# ML630Q466 register map
Vendor: LAPIS Semiconductor Co.,Ltd.; File version: 1.00
CPU: CM0PLUS r0p1, little endian, no MPU, no FPU, 2 interrupt priority bits
Registers are 32-bit, read-write, no defined reset value unless marked. A register's access mark holds for its fields unless they carry their own. Offsets are from the block's base; [hi:lo] are bit positions; {n}, {i} and the like mark numbered series.

## RESET
Base 0x5C000200
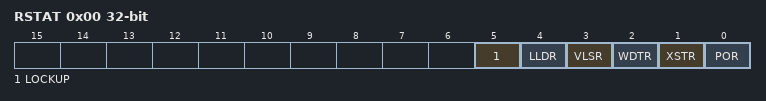
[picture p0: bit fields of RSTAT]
0x00 RSTAT — Reset status register
  [5] LOCKUP, [4] LLDR, [3] VLSR, [2] WDTR, [1] XSTR, [0] POR
0x04 LOCKUPEN — LOCKUP reset setting register
  [0] EN

## CLKCNT
Base 0x5C000300
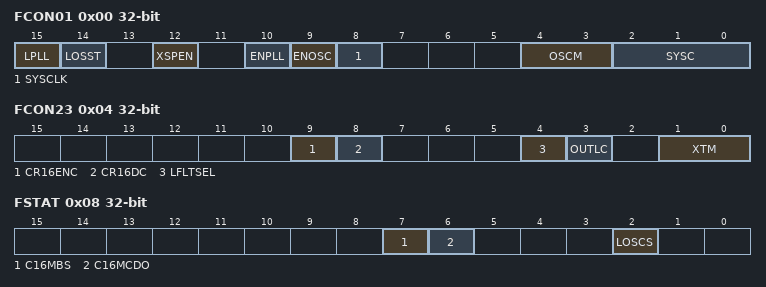
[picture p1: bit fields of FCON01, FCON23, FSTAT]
0x00 FCON01 access per field — Frequency control register 01
  [15] LPLL ro, [14] LOSST ro, [12] XSPEN rw, [10] ENPLL rw, [9] ENOSC rw, [8] SYSCLK rw, [4:3] OSCM rw, [2:0] SYSC rw
0x04 FCON23 — Frequency control register 23
  [9] CR16ENC, [8] CR16DC, [4] LFLTSEL, [3] OUTLC, [1:0] XTM
0x08 FSTAT ro — Frequency status register
  [7] C16MBS, [6] C16MCDO, [2] LOSCS

## NINT
Base 0x5C000100
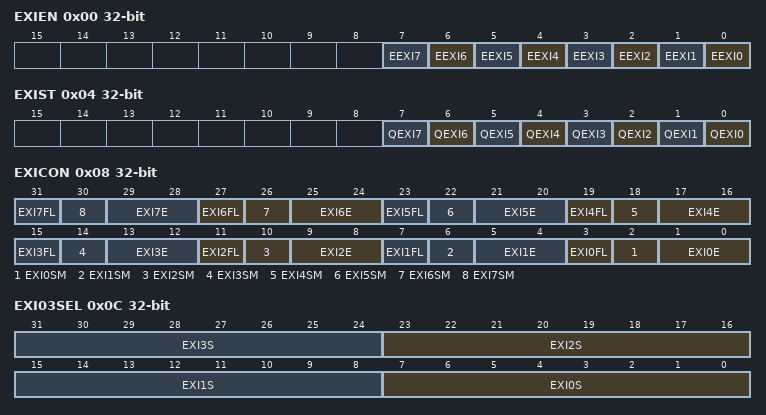
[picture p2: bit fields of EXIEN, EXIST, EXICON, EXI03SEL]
0x00 EXIEN — External interrupt enable register
  [n] EEXI{n} (n=0..7)
0x04 EXIST — External Interrupt status register
  [n] QEXI{n} (n=0..7)
0x08 EXICON — External interrupt control register
  [4n+3] EXI{n}FL (n=0..7), [4n+2] EXI{n}SM (n=0..7), [4n+1:4n] EXI{n}E (n=0..7)
0x0C EXI03SEL — External interrupt 03 selection register
  [8n+7:8n] EXI{n}S (n=0..3)
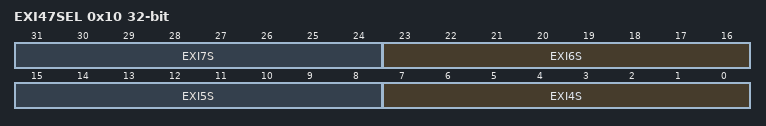
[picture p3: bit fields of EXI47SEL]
0x10 EXI47SEL — External interrupt 47 selection register
  [8n-25:8n-32] EXI{n}S (n=4..7)

## DMAC
Base 0x47000000
0x00 DMAMOD — DMA mode register
  [0] PRI
0x04 DMASTA ro — DMA status register
  [1:0] STA
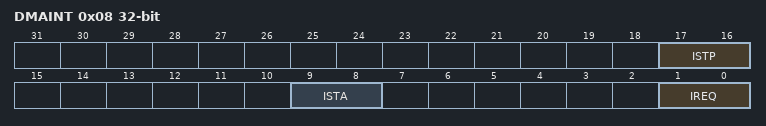
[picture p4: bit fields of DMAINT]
0x08 DMAINT ro — DMA end status register
  [17:16] ISTP, [9:8] ISTA, [1:0] IREQ

## DMAC0
Base 0x47000100
0x00 DMACMSK0 — DMA channel mask register
  [0] MSK
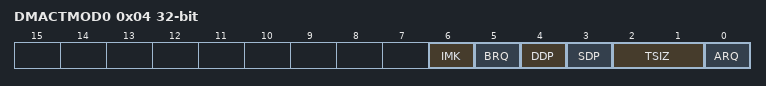
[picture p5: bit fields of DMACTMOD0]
0x04 DMACTMOD0 — DMA transfer mode register
  [6] IMK, [5] BRQ, [4] DDP, [3] SDP, [2:1] TSIZ, [0] ARQ
0x08 DMACSAD0 — DMA transfer source address register
  [31:0] CSAD
0x0C DMACDAD0 — DMA transfer destination address register
  [31:0] CDAD
0x10 DMACSIZ0 — DMA transfer count register
  [16:0] CSIZ
0x14 DMACCINT0 — DMA end status clear register
  [31:0] CCINT

## DMAC1
Base 0x47000200
0x00 DMACMSK1 — DMA channel mask register
  [0] MSK
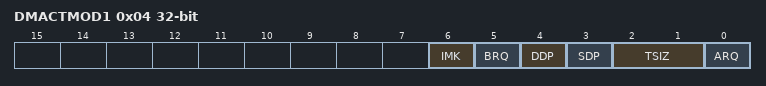
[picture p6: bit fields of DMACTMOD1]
0x04 DMACTMOD1 — DMA transfer mode register
  [6] IMK, [5] BRQ, [4] DDP, [3] SDP, [2:1] TSIZ, [0] ARQ
0x08 DMACSAD1 — DMA transfer source address register
  [31:0] CSAD
0x0C DMACDAD1 — DMA transfer destination address register
  [31:0] CDAD
0x10 DMACSIZ1 — DMA transfer count register
  [16:0] CSIZ
0x14 DMACCINT1 — DMA end status clear register
  [31:0] CCINT

## LTBC
Base 0x5C002100
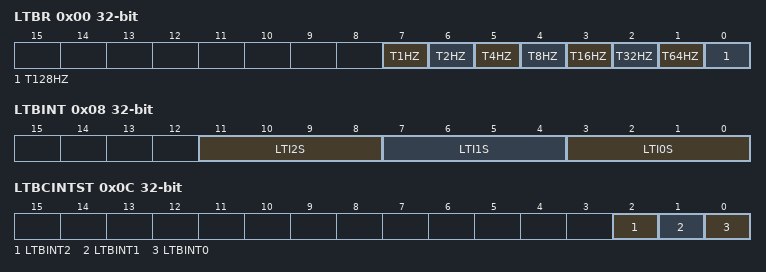
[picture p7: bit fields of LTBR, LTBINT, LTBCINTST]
0x00 LTBR — Low-speed time base counter register
  [7] T1HZ, [6] T2HZ, [5] T4HZ, [4] T8HZ, [3] T16HZ, [2] T32HZ, [1] T64HZ, [0] T128HZ
0x04 LTBADJ — Low-speed time base counter frequency adjustment register
  [10:0] LADJ
0x08 LTBINT — Low-speed time base counter interrupt select resister
  [11:8] LTI2S, [7:4] LTI1S, [3:0] LTI0S
0x0C LTBCINTST — Low-speed time base counter interrupt status register
  [2] LTBINT2, [1] LTBINT1, [0] LTBINT0

## TIMER
Base 0x5C001000
0x00 TM0D — Timer 0 data register
  [15:0] TnD
0x04 TM0C — Timer 0 counter register
  [15:0] TnC
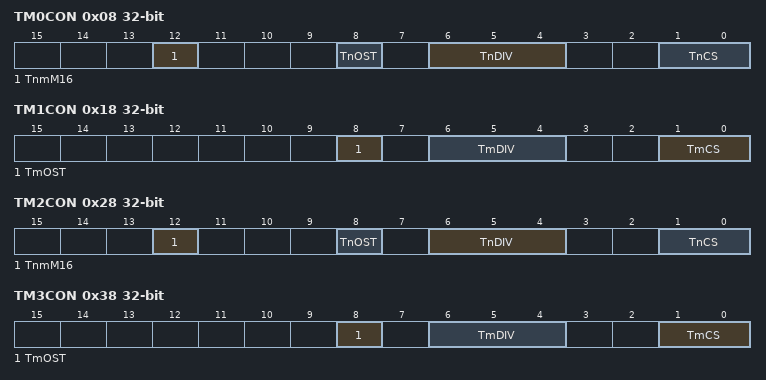
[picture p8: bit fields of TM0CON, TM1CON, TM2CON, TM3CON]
0x08 TM0CON — Timer 0 control register
  [12] TnmM16, [8] TnOST, [6:4] TnDIV, [1:0] TnCS
0x10 TM1D — Timer 1 data register
  [7:0] TmD
0x14 TM1C — Timer 1 counter register
  [7:0] TmC
0x18 TM1CON — Timer 1 control register
  [8] TmOST, [6:4] TmDIV, [1:0] TmCS
0x20 TM2D — Timer 2 data register
  [15:0] TnD
0x24 TM2C — Timer 2 counter register
  [15:0] TnC
0x28 TM2CON — Timer 2 control register
  [12] TnmM16, [8] TnOST, [6:4] TnDIV, [1:0] TnCS
0x30 TM3D — Timer 3 data register
  [7:0] TmD
0x34 TM3C — Timer 3 counter register
  [7:0] TmC
0x38 TM3CON — Timer 3 control register
  [8] TmOST, [6:4] TmDIV, [1:0] TmCS
0x40 TM4D — Timer 4 data register
  [15:0] TnD
0x44 TM4C — Timer 4 counter register
  [15:0] TnC
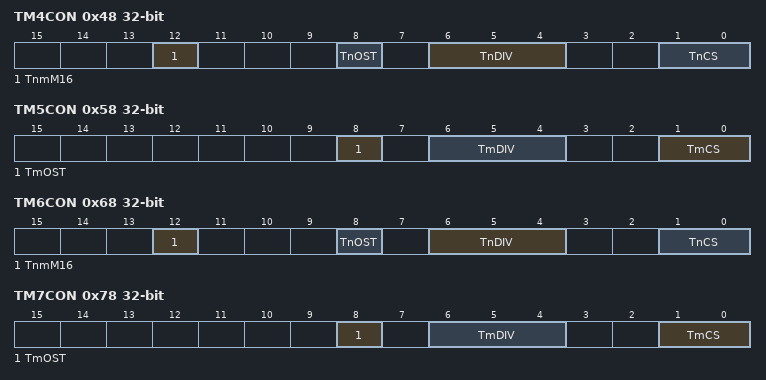
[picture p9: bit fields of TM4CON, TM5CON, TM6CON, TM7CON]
0x48 TM4CON — Timer 4 control register
  [12] TnmM16, [8] TnOST, [6:4] TnDIV, [1:0] TnCS
0x50 TM5D — Timer 5 data register
  [7:0] TmD
0x54 TM5C — Timer 5 counter register
  [7:0] TmC
0x58 TM5CON — Timer 5 control register
  [8] TmOST, [6:4] TmDIV, [1:0] TmCS
0x60 TM6D — Timer 6 data register
  [15:0] TnD
0x64 TM6C — Timer 6 counter register
  [15:0] TnC
0x68 TM6CON — Timer 6 control register
  [12] TnmM16, [8] TnOST, [6:4] TnDIV, [1:0] TnCS
0x70 TM7D — Timer 7 data register
  [7:0] TmD
0x74 TM7C — Timer 7 counter register
  [7:0] TmC
0x78 TM7CON — Timer 7 control register
  [8] TmOST, [6:4] TmDIV, [1:0] TmCS
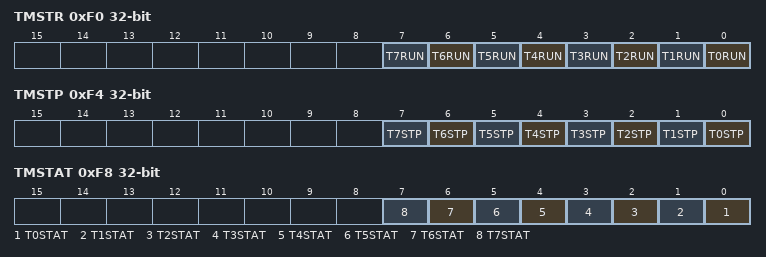
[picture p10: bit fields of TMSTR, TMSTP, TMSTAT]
0xF0 TMSTR wo — Timer start register
  [n] T{n}RUN (n=0..7)
0xF4 TMSTP wo — Timer stop register
  [n] T{n}STP (n=0..7)
0xF8 TMSTAT ro — Timer status register
  [n] T{n}STAT (n=0..7)
